# RP2040 register map
Vendor: Raspberry Pi; Series: RP; File version: 0.1
CPU: CM0PLUS r0p1, little endian, MPU, no FPU, VTOR, 2 interrupt priority bits, 32 interrupts
Registers are 32-bit, read-write, reset 0x0 unless marked. A register's access mark holds for its fields unless they carry their own. Offsets are from the block's base; [hi:lo] are bit positions; {n}, {i} and the like mark numbered series; 'fields as' and 'values as' point back to an identical list; <NAME> marks a mode.

## SIO — Single-cycle IO block Provides core-local and inter-core hardware for the two processors, with single-cycle access.
Base 0xD0000000
0x00 CPUID reset not defined — Processor core identifier
  [31:0] CPUID ro — Value is 0 when read from processor core 0, and 1 when read from processor core 1.
0x04 GPIO_IN — Input value for GPIO pins
  [29:0] GPIO_IN ro — Input value for GPIO0...29
0x08 GPIO_HI_IN — Input value for QSPI pins
  [5:0] GPIO_HI_IN ro — Input value on QSPI IO in order 0..5: SCLK, SSn, SD0, SD1, SD2, SD3
0x10 GPIO_OUT — GPIO output value
  [29:0] GPIO_OUT — Set output level (1/0 -> high/low) for GPIO0...29. Reading back gives the last value written, NOT the input value from the pins. If core 0 and core 1 both write to GPIO_OUT simultaneously (or to a SET/CLR/XOR alias), the result is as though the write from core 0 took place first, and the write from core 1 was then applied to that intermediate result.
0x14 GPIO_OUT_SET — GPIO output value set
  [29:0] GPIO_OUT_SET wo — Perform an atomic bit-set on GPIO_OUT, i.e. `GPIO_OUT |= wdata`
0x18 GPIO_OUT_CLR — GPIO output value clear
  [29:0] GPIO_OUT_CLR wo — Perform an atomic bit-clear on GPIO_OUT, i.e. `GPIO_OUT &= ~wdata`
0x1C GPIO_OUT_XOR — GPIO output value XOR
  [29:0] GPIO_OUT_XOR wo — Perform an atomic bitwise XOR on GPIO_OUT, i.e. `GPIO_OUT ^= wdata`
0x20 GPIO_OE — GPIO output enable
  [29:0] GPIO_OE — Set output enable (1/0 -> output/input) for GPIO0...29. Reading back gives the last value written. If core 0 and core 1 both write to GPIO_OE simultaneously (or to a SET/CLR/XOR alias), the result is as though the write from core 0 took place first, and the write from core 1 was then applied to that intermediate result.
0x24 GPIO_OE_SET — GPIO output enable set
  [29:0] GPIO_OE_SET wo — Perform an atomic bit-set on GPIO_OE, i.e. `GPIO_OE |= wdata`
0x28 GPIO_OE_CLR — GPIO output enable clear
  [29:0] GPIO_OE_CLR wo — Perform an atomic bit-clear on GPIO_OE, i.e. `GPIO_OE &= ~wdata`
0x2C GPIO_OE_XOR — GPIO output enable XOR
  [29:0] GPIO_OE_XOR wo — Perform an atomic bitwise XOR on GPIO_OE, i.e. `GPIO_OE ^= wdata`
0x30 GPIO_HI_OUT — QSPI output value
  [5:0] GPIO_HI_OUT — Set output level (1/0 -> high/low) for QSPI IO0...5. Reading back gives the last value written, NOT the input value from the pins. If core 0 and core 1 both write to GPIO_HI_OUT simultaneously (or to a SET/CLR/XOR alias), the result is as though the write from core 0 took place first, and the write from core 1 was then applied to that intermediate result.
0x34 GPIO_HI_OUT_SET — QSPI output value set
  [5:0] GPIO_HI_OUT_SET wo — Perform an atomic bit-set on GPIO_HI_OUT, i.e. `GPIO_HI_OUT |= wdata`
0x38 GPIO_HI_OUT_CLR — QSPI output value clear
  [5:0] GPIO_HI_OUT_CLR wo — Perform an atomic bit-clear on GPIO_HI_OUT, i.e. `GPIO_HI_OUT &= ~wdata`
0x3C GPIO_HI_OUT_XOR — QSPI output value XOR
  [5:0] GPIO_HI_OUT_XOR wo — Perform an atomic bitwise XOR on GPIO_HI_OUT, i.e. `GPIO_HI_OUT ^= wdata`
0x40 GPIO_HI_OE — QSPI output enable
  [5:0] GPIO_HI_OE — Set output enable (1/0 -> output/input) for QSPI IO0...5. Reading back gives the last value written. If core 0 and core 1 both write to GPIO_HI_OE simultaneously (or to a SET/CLR/XOR alias), the result is as though the write from core 0 took place first, and the write from core 1 was then applied to that intermediate result.
0x44 GPIO_HI_OE_SET — QSPI output enable set
  [5:0] GPIO_HI_OE_SET wo — Perform an atomic bit-set on GPIO_HI_OE, i.e. `GPIO_HI_OE |= wdata`
0x48 GPIO_HI_OE_CLR — QSPI output enable clear
  [5:0] GPIO_HI_OE_CLR wo — Perform an atomic bit-clear on GPIO_HI_OE, i.e. `GPIO_HI_OE &= ~wdata`
0x4C GPIO_HI_OE_XOR — QSPI output enable XOR
  [5:0] GPIO_HI_OE_XOR wo — Perform an atomic bitwise XOR on GPIO_HI_OE, i.e. `GPIO_HI_OE ^= wdata`
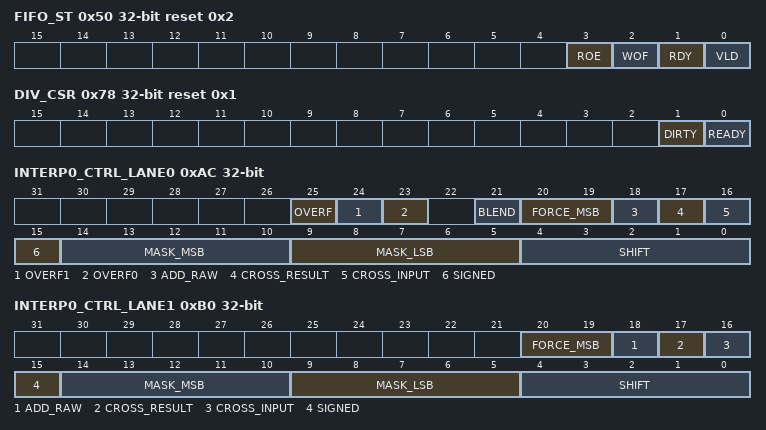
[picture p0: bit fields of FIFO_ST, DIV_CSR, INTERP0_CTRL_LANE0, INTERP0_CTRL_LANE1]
0x50 FIFO_ST reset 0x2 — Status register for inter-core FIFOs (mailboxes). There is one FIFO in the core 0 -> core 1 direction, and one core 1 -> core 0. Both are 32 bits wide and 8 words deep. Core 0 can see the read side of the 1->0 FIFO (RX), and the write side of 0->1 FIFO (TX). Core 1 can see the read side of the 0->1 FIFO (RX), and the write side of 1->0 FIFO (TX). The SIO IRQ for each core is the logical OR of the VLD, WOF and ROE fields of its FIFO_ST register.
  [3] ROE write-1-clears — Sticky flag indicating the RX FIFO was read when empty. This read was ignored by the FIFO.
  [2] WOF write-1-clears — Sticky flag indicating the TX FIFO was written when full. This write was ignored by the FIFO.
  [1] RDY ro — Value is 1 if this core's TX FIFO is not full (i.e. if FIFO_WR is ready for more data)
  [0] VLD ro — Value is 1 if this core's RX FIFO is not empty (i.e. if FIFO_RD is valid)
0x54 FIFO_WR — Write access to this core's TX FIFO
  [31:0] FIFO_WR wo
0x58 FIFO_RD reset not defined — Read access to this core's RX FIFO
  [31:0] FIFO_RD ro read-modifies
0x5C SPINLOCK_ST — Spinlock state A bitmap containing the state of all 32 spinlocks (1=locked). Mainly intended for debugging.
  [31:0] SPINLOCK_ST ro
0x60 DIV_UDIVIDEND — Divider unsigned dividend Write to the DIVIDEND operand of the divider, i.e. the p in `p / q`. Any operand write starts a new calculation. The results appear in QUOTIENT, REMAINDER. UDIVIDEND/SDIVIDEND are aliases of the same internal register. The U alias starts an unsigned calculation, and the S alias starts a signed calculation.
0x64 DIV_UDIVISOR — Divider unsigned divisor Write to the DIVISOR operand of the divider, i.e. the q in `p / q`. Any operand write starts a new calculation. The results appear in QUOTIENT, REMAINDER. UDIVISOR/SDIVISOR are aliases of the same internal register. The U alias starts an unsigned calculation, and the S alias starts a signed calculation.
0x68 DIV_SDIVIDEND — Divider signed dividend The same as UDIVIDEND, but starts a signed calculation, rather than unsigned.
0x6C DIV_SDIVISOR — Divider signed divisor The same as UDIVISOR, but starts a signed calculation, rather than unsigned.
0x70 DIV_QUOTIENT — Divider result quotient The result of `DIVIDEND / DIVISOR` (division). Contents undefined while CSR_READY is low. For signed calculations, QUOTIENT is negative when the signs of DIVIDEND and DIVISOR differ. This register can be written to directly, for context save/restore purposes. This halts any in-progress calculation and sets the CSR_READY and CSR_DIRTY flags. Reading from QUOTIENT clears the CSR_DIRTY flag, so should read results in the order REMAINDER, QUOTIENT if CSR_DIRTY is used.
0x74 DIV_REMAINDER — Divider result remainder The result of `DIVIDEND % DIVISOR` (modulo). Contents undefined while CSR_READY is low. For signed calculations, REMAINDER is negative only when DIVIDEND is negative. This register can be written to directly, for context save/restore purposes. This halts any in-progress calculation and sets the CSR_READY and CSR_DIRTY flags.
0x78 DIV_CSR reset 0x1 — Control and status register for divider.
  [1] DIRTY ro — Changes to 1 when any register is written, and back to 0 when QUOTIENT is read. Software can use this flag to make save/restore more efficient (skip if not DIRTY). If the flag is used in this way, it's recommended to either read QUOTIENT only, or REMAINDER and then QUOTIENT, to prevent data loss on context switch.
  [0] READY ro — Reads as 0 when a calculation is in progress, 1 otherwise. Writing an operand (xDIVIDEND, xDIVISOR) will immediately start a new calculation, no matter if one is already in progress. Writing to a result register will immediately terminate any in-progress calculation and set the READY and DIRTY flags.
0x80 INTERP0_ACCUM0 — Read/write access to accumulator 0
0x84 INTERP0_ACCUM1 — Read/write access to accumulator 1
{0x88+4i} INTERP0_BASE{i} (i=0..2) — Read/write access to BASE{i} register.
0x94 INTERP0_POP_LANE0 — Read LANE0 result, and simultaneously write lane results to both accumulators (POP).
  [31:0] INTERP0_POP_LANE0 ro
0x98 INTERP0_POP_LANE1 — Read LANE1 result, and simultaneously write lane results to both accumulators (POP).
  [31:0] INTERP0_POP_LANE1 ro
0x9C INTERP0_POP_FULL — Read FULL result, and simultaneously write lane results to both accumulators (POP).
  [31:0] INTERP0_POP_FULL ro
0xA0 INTERP0_PEEK_LANE0 — Read LANE0 result, without altering any internal state (PEEK).
  [31:0] INTERP0_PEEK_LANE0 ro
0xA4 INTERP0_PEEK_LANE1 — Read LANE1 result, without altering any internal state (PEEK).
  [31:0] INTERP0_PEEK_LANE1 ro
0xA8 INTERP0_PEEK_FULL — Read FULL result, without altering any internal state (PEEK).
  [31:0] INTERP0_PEEK_FULL ro
0xAC INTERP0_CTRL_LANE0 — Control register for lane 0
  [25] OVERF ro — Set if either OVERF0 or OVERF1 is set.
  [24] OVERF1 ro — Indicates if any masked-off MSBs in ACCUM1 are set.
  [23] OVERF0 ro — Indicates if any masked-off MSBs in ACCUM0 are set.
  [21] BLEND — Only present on INTERP0 on each core. If BLEND mode is enabled: - LANE1 result is a linear interpolation between BASE0 and BASE1, controlled by the 8 LSBs of lane 1 shift and mask value (a fractional number between 0 and 255/256ths) - LANE0 result does not have BASE0 added (yields only the 8 LSBs of lane 1 shift+mask value) - FULL result does not have lane 1 shift+mask value added (BASE2 + lane 0 shift+mask) LANE1 SIGNED flag controls whether the interpolation is signed or unsigned.
  [20:19] FORCE_MSB — ORed into bits 29:28 of the lane result presented to the processor on the bus. No effect on the internal 32-bit datapath. Handy for using a lane to generate sequence of pointers into flash or SRAM.
  [18] ADD_RAW — If 1, mask + shift is bypassed for LANE0 result. This does not affect FULL result.
  [17] CROSS_RESULT — If 1, feed the opposite lane's result into this lane's accumulator on POP.
  [16] CROSS_INPUT — If 1, feed the opposite lane's accumulator into this lane's shift + mask hardware. Takes effect even if ADD_RAW is set (the CROSS_INPUT mux is before the shift+mask bypass)
  [15] SIGNED — If SIGNED is set, the shifted and masked accumulator value is sign-extended to 32 bits before adding to BASE0, and LANE0 PEEK/POP appear extended to 32 bits when read by processor.
  [14:10] MASK_MSB — The most-significant bit allowed to pass by the mask (inclusive) Setting MSB < LSB may cause chip to turn inside-out
  [9:5] MASK_LSB — The least-significant bit allowed to pass by the mask (inclusive)
  [4:0] SHIFT — Logical right-shift applied to accumulator before masking
0xB0 INTERP0_CTRL_LANE1 — Control register for lane 1
  [20:19] FORCE_MSB — ORed into bits 29:28 of the lane result presented to the processor on the bus. No effect on the internal 32-bit datapath. Handy for using a lane to generate sequence of pointers into flash or SRAM.
  [18] ADD_RAW — If 1, mask + shift is bypassed for LANE1 result. This does not affect FULL result.
  [17] CROSS_RESULT — If 1, feed the opposite lane's result into this lane's accumulator on POP.
  [16] CROSS_INPUT — If 1, feed the opposite lane's accumulator into this lane's shift + mask hardware. Takes effect even if ADD_RAW is set (the CROSS_INPUT mux is before the shift+mask bypass)
  [15] SIGNED — If SIGNED is set, the shifted and masked accumulator value is sign-extended to 32 bits before adding to BASE1, and LANE1 PEEK/POP appear extended to 32 bits when read by processor.
  [14:10] MASK_MSB — The most-significant bit allowed to pass by the mask (inclusive) Setting MSB < LSB may cause chip to turn inside-out
  [9:5] MASK_LSB — The least-significant bit allowed to pass by the mask (inclusive)
  [4:0] SHIFT — Logical right-shift applied to accumulator before masking
0xB4 INTERP0_ACCUM0_ADD — Values written here are atomically added to ACCUM0 Reading yields lane 0's raw shift and mask value (BASE0 not added).
  [23:0] INTERP0_ACCUM0_ADD
0xB8 INTERP0_ACCUM1_ADD — Values written here are atomically added to ACCUM1 Reading yields lane 1's raw shift and mask value (BASE1 not added).
  [23:0] INTERP0_ACCUM1_ADD
0xBC INTERP0_BASE_1AND0 — On write, the lower 16 bits go to BASE0, upper bits to BASE1 simultaneously. Each half is sign-extended to 32 bits if that lane's SIGNED flag is set.
  [31:0] INTERP0_BASE_1AND0 wo
0xC0 INTERP1_ACCUM0 — Read/write access to accumulator 0
0xC4 INTERP1_ACCUM1 — Read/write access to accumulator 1
{0xC8+4i} INTERP1_BASE{i} (i=0..2) — Read/write access to BASE{i} register.
0xD4 INTERP1_POP_LANE0 — Read LANE0 result, and simultaneously write lane results to both accumulators (POP).
  [31:0] INTERP1_POP_LANE0 ro
0xD8 INTERP1_POP_LANE1 — Read LANE1 result, and simultaneously write lane results to both accumulators (POP).
  [31:0] INTERP1_POP_LANE1 ro
0xDC INTERP1_POP_FULL — Read FULL result, and simultaneously write lane results to both accumulators (POP).
  [31:0] INTERP1_POP_FULL ro
0xE0 INTERP1_PEEK_LANE0 — Read LANE0 result, without altering any internal state (PEEK).
  [31:0] INTERP1_PEEK_LANE0 ro
0xE4 INTERP1_PEEK_LANE1 — Read LANE1 result, without altering any internal state (PEEK).
  [31:0] INTERP1_PEEK_LANE1 ro
0xE8 INTERP1_PEEK_FULL — Read FULL result, without altering any internal state (PEEK).
  [31:0] INTERP1_PEEK_FULL ro
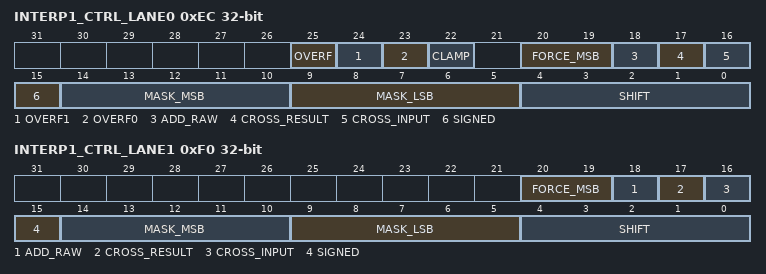
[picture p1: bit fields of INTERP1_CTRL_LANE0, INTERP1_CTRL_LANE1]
0xEC INTERP1_CTRL_LANE0 — Control register for lane 0
  [25] OVERF ro — Set if either OVERF0 or OVERF1 is set.
  [24] OVERF1 ro — Indicates if any masked-off MSBs in ACCUM1 are set.
  [23] OVERF0 ro — Indicates if any masked-off MSBs in ACCUM0 are set.
  [22] CLAMP — Only present on INTERP1 on each core. If CLAMP mode is enabled: - LANE0 result is shifted and masked ACCUM0, clamped by a lower bound of BASE0 and an upper bound of BASE1. - Signedness of these comparisons is determined by LANE0_CTRL_SIGNED
  [20:19] FORCE_MSB — ORed into bits 29:28 of the lane result presented to the processor on the bus. No effect on the internal 32-bit datapath. Handy for using a lane to generate sequence of pointers into flash or SRAM.
  [18] ADD_RAW — If 1, mask + shift is bypassed for LANE0 result. This does not affect FULL result.
  [17] CROSS_RESULT — If 1, feed the opposite lane's result into this lane's accumulator on POP.
  [16] CROSS_INPUT — If 1, feed the opposite lane's accumulator into this lane's shift + mask hardware. Takes effect even if ADD_RAW is set (the CROSS_INPUT mux is before the shift+mask bypass)
  [15] SIGNED — If SIGNED is set, the shifted and masked accumulator value is sign-extended to 32 bits before adding to BASE0, and LANE0 PEEK/POP appear extended to 32 bits when read by processor.
  [14:10] MASK_MSB — The most-significant bit allowed to pass by the mask (inclusive) Setting MSB < LSB may cause chip to turn inside-out
  [9:5] MASK_LSB — The least-significant bit allowed to pass by the mask (inclusive)
  [4:0] SHIFT — Logical right-shift applied to accumulator before masking
0xF0 INTERP1_CTRL_LANE1 — Control register for lane 1
  fields as INTERP0_CTRL_LANE1
0xF4 INTERP1_ACCUM0_ADD — Values written here are atomically added to ACCUM0 Reading yields lane 0's raw shift and mask value (BASE0 not added).
  [23:0] INTERP1_ACCUM0_ADD
0xF8 INTERP1_ACCUM1_ADD — Values written here are atomically added to ACCUM1 Reading yields lane 1's raw shift and mask value (BASE1 not added).
  [23:0] INTERP1_ACCUM1_ADD
0xFC INTERP1_BASE_1AND0 — On write, the lower 16 bits go to BASE0, upper bits to BASE1 simultaneously. Each half is sign-extended to 32 bits if that lane's SIGNED flag is set.
  [31:0] INTERP1_BASE_1AND0 wo
{0x100+4i} SPINLOCK{i} (i=0..31) — Reading from a spinlock address will: - Return 0 if lock is already locked - Otherwise return nonzero, and simultaneously claim the lock Writing (any value) releases the lock. If core 0 and core 1 attempt to claim the same lock simultaneously, core 0 wins. The value returned on success is 0x1 << lock number.
  [31:0] SPINLOCK{i} read-modifies
